VERSION ""

NS_ :

BS_:

BU_: XXX

BO_ 80 GW_50: 8 XXX
 SG_ SRS_DriverBuckleSwitchStatus : 0|1@0+ (1,0) [0|1] "" XXX

BO_ 368 GW_170: 8 XXX
 SG_ EPS_ActualTorsionBarTorq : 7|16@0- (1,0) [0|0] "" XXX

BO_ 378 GW_17A: 8 XXX
 SG_ ESP_VehicleSpeed : 7|16@0+ (0.01,0) [0|0] "km/h" XXX

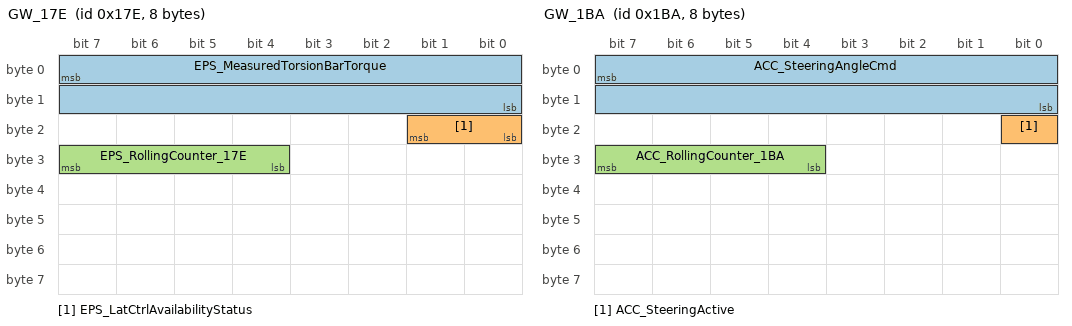
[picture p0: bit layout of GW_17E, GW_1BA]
BO_ 382 GW_17E: 8 XXX
 SG_ EPS_MeasuredTorsionBarTorque : 7|16@0- (1,0) [0|0] "" XXX
 SG_ EPS_LatCtrlAvailabilityStatus : 17|2@0+ (1,0) [0|3] "" XXX
 SG_ EPS_RollingCounter_17E : 31|4@0+ (1,0) [0|15] "" XXX

BO_ 384 GW_180: 8 XXX
 SG_ SAS_SteeringAngle : 7|16@0- (0.1,0) [0|0] "deg" XXX
 SG_ SAS_SteeringAngleSpeed : 23|16@0- (1,0) [0|0] "deg/s" XXX

BO_ 391 GW_187: 8 XXX
 SG_ ESP_VehicleSpeed : 7|16@0+ (0.01,0) [0|0] "km/h" XXX

BO_ 406 GW_196: 8 XXX
 SG_ EMS_BrakePedalStatus : 0|1@0+ (1,0) [0|1] "" XXX
 SG_ EMS_RealAccPedal : 15|8@0+ (1,0) [0|0] "" XXX

BO_ 422 GW_1A6: 8 XXX
 SG_ EMS_BrakePedalStatus : 0|1@0+ (1,0) [0|1] "" XXX

BO_ 442 GW_1BA: 8 XXX
 SG_ ACC_SteeringAngleCmd : 7|16@0- (0.1,0) [0|0] "deg" XXX
 SG_ ACC_SteeringActive : 16|1@0+ (1,0) [0|1] "" XXX
 SG_ ACC_RollingCounter_1BA : 31|4@0+ (1,0) [0|15] "" XXX

BO_ 454 GW_1C6: 8 XXX
 SG_ EMS_RealAccPedal : 7|8@0+ (1,0) [0|0] "" XXX

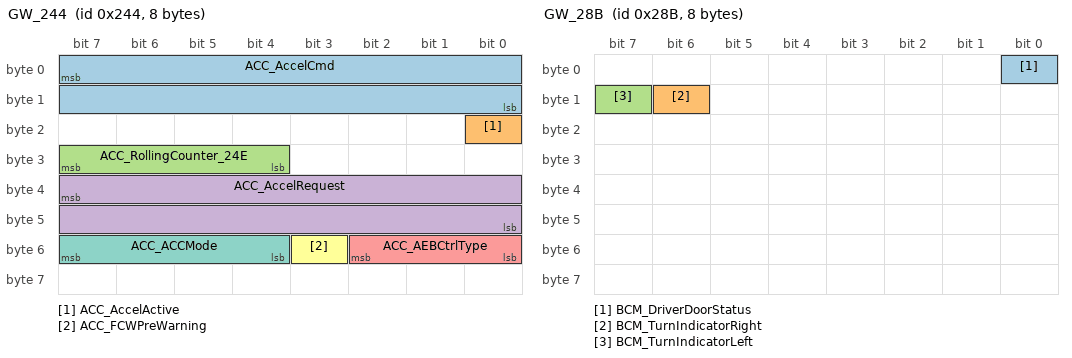
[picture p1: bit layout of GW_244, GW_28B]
BO_ 580 GW_244: 8 XXX
 SG_ ACC_AccelCmd : 7|16@0- (0.001,0) [-20|20] "m/s^2" XXX
 SG_ ACC_AccelActive : 16|1@0+ (1,0) [0|1] "" XXX
 SG_ ACC_RollingCounter_24E : 31|4@0+ (1,0) [0|15] "" XXX
 SG_ ACC_AccelRequest : 39|16@0- (1,0) [0|0] "" XXX
 SG_ ACC_AEBCtrlType : 50|3@0+ (1,0) [0|7] "" XXX
 SG_ ACC_FCWPreWarning : 51|1@0+ (1,0) [0|1] "" XXX
 SG_ ACC_ACCMode : 55|4@0+ (1,0) [0|15] "" XXX

BO_ 591 GW_24F: 8 XXX
 SG_ EPS_EPSFailed : 0|1@0+ (1,0) [0|1] "" XXX

BO_ 651 GW_28B: 8 XXX
 SG_ BCM_DriverDoorStatus : 0|1@0+ (1,0) [0|1] "" XXX
 SG_ BCM_TurnIndicatorRight : 14|1@0+ (1,0) [0|1] "" XXX
 SG_ BCM_TurnIndicatorLeft : 15|1@0+ (1,0) [0|1] "" XXX

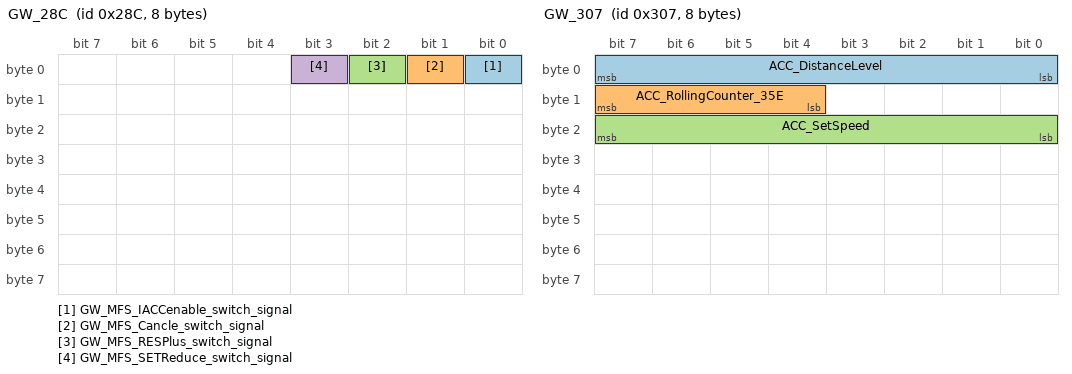
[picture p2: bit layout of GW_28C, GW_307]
BO_ 652 GW_28C: 8 XXX
 SG_ GW_MFS_IACCenable_switch_signal : 0|1@0+ (1,0) [0|1] "" XXX
 SG_ GW_MFS_Cancle_switch_signal : 1|1@0+ (1,0) [0|1] "" XXX
 SG_ GW_MFS_RESPlus_switch_signal : 2|1@0+ (1,0) [0|1] "" XXX
 SG_ GW_MFS_SETReduce_switch_signal : 3|1@0+ (1,0) [0|1] "" XXX

BO_ 775 GW_307: 8 XXX
 SG_ ACC_DistanceLevel : 7|8@0+ (1,0) [0|0] "" XXX
 SG_ ACC_RollingCounter_35E : 15|4@0+ (1,0) [0|15] "" XXX
 SG_ ACC_SetSpeed : 23|8@0+ (1,0) [0|0] "km/h" XXX

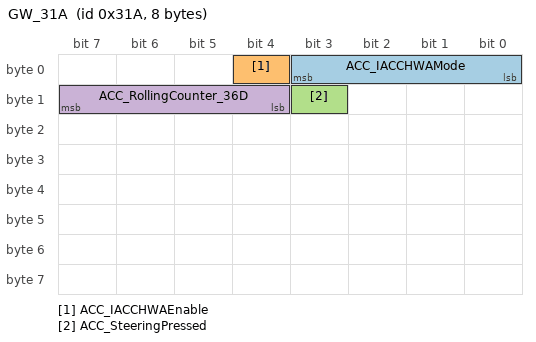
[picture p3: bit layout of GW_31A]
BO_ 794 GW_31A: 8 XXX
 SG_ ACC_IACCHWAMode : 3|4@0+ (1,0) [0|15] "" XXX
 SG_ ACC_IACCHWAEnable : 4|1@0+ (1,0) [0|1] "" XXX
 SG_ ACC_SteeringPressed : 11|1@0+ (1,0) [0|1] "" XXX
 SG_ ACC_RollingCounter_36D : 15|4@0+ (1,0) [0|15] "" XXX

BO_ 824 GW_338: 8 XXX
 SG_ TCU_GearForDisplay : 7|8@0+ (1,0) [0|0] "" XXX
